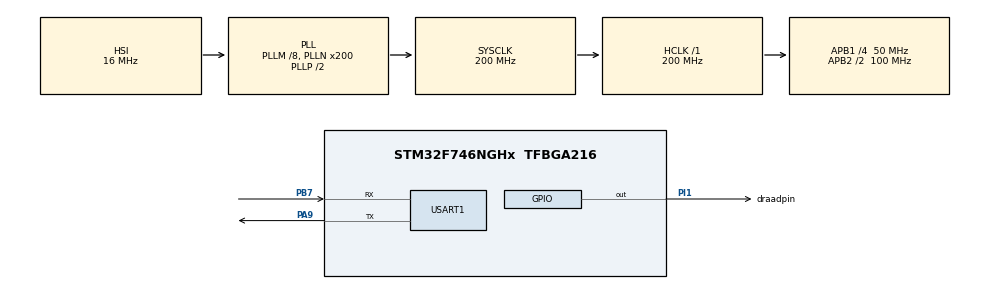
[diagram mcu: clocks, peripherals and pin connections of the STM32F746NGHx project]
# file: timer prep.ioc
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Mcu.Family=STM32F7
Mcu.Name=STM32F746NGHx
Mcu.Package=TFBGA216
NVIC.PriorityGroup=NVIC_PRIORITYGROUP_4
NVIC.TIM1_UP_TIM10_IRQn=true\:15\:0\:false\:false\:true\:false\:true
NVIC.TIM2_IRQn=true\:0\:0\:false\:false\:true\:true\:true
NVIC.TimeBase=TIM1_UP_TIM10_IRQn
NVIC.TimeBaseIP=TIM1
PA9.Mode=Asynchronous
PA9.Signal=USART1_TX
PB7.Mode=Asynchronous
PB7.Signal=USART1_RX
PI1.GPIO_Label=draadpin
PI1.Signal=GPIO_Output
ProjectManager.HeapSize=0x200
ProjectManager.StackSize=0x400
ProjectManager.TargetToolchain=STM32CubeIDE
RCC.AHBFreq_Value=200000000
RCC.APB1CLKDivider=RCC_HCLK_DIV4
RCC.APB1Freq_Value=50000000
RCC.APB1TimFreq_Value=100000000
RCC.APB2CLKDivider=RCC_HCLK_DIV2
RCC.APB2Freq_Value=100000000
RCC.APB2TimFreq_Value=200000000
RCC.CortexFreq_Value=200000000
RCC.HCLKFreq_Value=200000000
RCC.HSE_VALUE=25000000
RCC.HSI_VALUE=16000000
RCC.LSE_VALUE=32768
RCC.PLL48CLockSelection=RCC_CLK48SOURCE_PLLSAIP
RCC.PLLI2SN=100
RCC.PLLM=8
RCC.PLLN=200
RCC.PLLQ=9
RCC.PLLSAIN=384
RCC.PLLSAIP=RCC_PLLSAIP_DIV8
RCC.PLLSAIR=5
RCC.PLLSAIRDiv=RCC_PLLSAIDIVR_8
RCC.SDMMCClockSelection=RCC_SDMMC1CLKSOURCE_CLK48
RCC.SYSCLKFreq_VALUE=200000000
RCC.SYSCLKSource=RCC_SYSCLKSOURCE_PLLCLK
RCC.USBFreq_Value=96000000
RCC.VCOOutputFreq_Value=400000000
TIM2.AutoReloadPreload=TIM_AUTORELOAD_PRELOAD_ENABLE
TIM2.CounterMode=TIM_COUNTERMODE_DOWN
TIM2.Period=10
USART1.VirtualMode-Asynchronous=VM_ASYNC
VP_SYS_VS_tim1.Mode=TIM1
VP_TIM2_VS_ClockSourceINT.Mode=Internal
board=STM32F746G-DISCO

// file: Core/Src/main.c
/* USER CODE BEGIN Header */
/**
 ******************************************************************************
 * @file           : main.c
 * @brief          : Main program body
 ******************************************************************************
 * @attention
 *
 * <h2><center>&copy; Copyright (c) 2023 STMicroelectronics.
 * All rights reserved.</center></h2>
 *
 * This software component is licensed by ST under Ultimate Liberty license
 * SLA0044, the "License"; You may not use this file except in compliance with
 * the License. You may obtain a copy of the License at:
 *                             www.st.com/SLA0044
 *
 ******************************************************************************
 */
/* USER CODE END Header */
#include "main.h"

TIM_HandleTypeDef htim2;

UART_HandleTypeDef huart1;

void SystemClock_Config(void);
static void MX_GPIO_Init(void);
static void MX_USART1_UART_Init(void);
static void MX_TIM2_Init(void);

int main(void)
{

  /* MCU Configuration--------------------------------------------------------*/

  /* Reset of all peripherals, Initializes the Flash interface and the Systick. */
  HAL_Init();

  /* Configure the system clock */
  SystemClock_Config();

  /* Initialize all configured peripherals */
  MX_GPIO_Init();
  MX_USART1_UART_Init();
  MX_TIM2_Init();
  /* USER CODE BEGIN 2 */

	HAL_TIM_Base_Start_IT(&htim2);

  /* USER CODE END 2 */

  /* Infinite loop */
	while (1)
	{

	}
}

void SystemClock_Config(void)
{
  RCC_OscInitTypeDef RCC_OscInitStruct = {0};
  RCC_ClkInitTypeDef RCC_ClkInitStruct = {0};
  RCC_PeriphCLKInitTypeDef PeriphClkInitStruct = {0};

  /** Configure the main internal regulator output voltage
  */
  __HAL_RCC_PWR_CLK_ENABLE();
  __HAL_PWR_VOLTAGESCALING_CONFIG(PWR_REGULATOR_VOLTAGE_SCALE1);
  /** Initializes the RCC Oscillators according to the specified parameters
  * in the RCC_OscInitTypeDef structure.
  */
  RCC_OscInitStruct.OscillatorType = RCC_OSCILLATORTYPE_HSI;
  RCC_OscInitStruct.HSIState = RCC_HSI_ON;
  RCC_OscInitStruct.HSICalibrationValue = RCC_HSICALIBRATION_DEFAULT;
  RCC_OscInitStruct.PLL.PLLState = RCC_PLL_ON;
  RCC_OscInitStruct.PLL.PLLSource = RCC_PLLSOURCE_HSI;
  RCC_OscInitStruct.PLL.PLLM = 8;
  RCC_OscInitStruct.PLL.PLLN = 200;
  RCC_OscInitStruct.PLL.PLLP = RCC_PLLP_DIV2;
  RCC_OscInitStruct.PLL.PLLQ = 9;
  if (HAL_RCC_OscConfig(&RCC_OscInitStruct) != HAL_OK)
  {
    Error_Handler();
  }
  /** Activate the Over-Drive mode
  */
  if (HAL_PWREx_EnableOverDrive() != HAL_OK)
  {
    Error_Handler();
  }
  /** Initializes the CPU, AHB and APB buses clocks
  */
  RCC_ClkInitStruct.ClockType = RCC_CLOCKTYPE_HCLK|RCC_CLOCKTYPE_SYSCLK
                              |RCC_CLOCKTYPE_PCLK1|RCC_CLOCKTYPE_PCLK2;
  RCC_ClkInitStruct.SYSCLKSource = RCC_SYSCLKSOURCE_PLLCLK;
  RCC_ClkInitStruct.AHBCLKDivider = RCC_SYSCLK_DIV1;
  RCC_ClkInitStruct.APB1CLKDivider = RCC_HCLK_DIV4;
  RCC_ClkInitStruct.APB2CLKDivider = RCC_HCLK_DIV2;

  if (HAL_RCC_ClockConfig(&RCC_ClkInitStruct, FLASH_LATENCY_6) != HAL_OK)
  {
    Error_Handler();
  }
  PeriphClkInitStruct.PeriphClockSelection = RCC_PERIPHCLK_USART1;
  PeriphClkInitStruct.Usart1ClockSelection = RCC_USART1CLKSOURCE_PCLK2;
  if (HAL_RCCEx_PeriphCLKConfig(&PeriphClkInitStruct) != HAL_OK)
  {
    Error_Handler();
  }
}

static void MX_TIM2_Init(void)
{

  TIM_ClockConfigTypeDef sClockSourceConfig = {0};
  TIM_MasterConfigTypeDef sMasterConfig = {0};

  htim2.Instance = TIM2;
  htim2.Init.Prescaler = 0;
  htim2.Init.CounterMode = TIM_COUNTERMODE_DOWN;
  htim2.Init.Period = 10;
  htim2.Init.ClockDivision = TIM_CLOCKDIVISION_DIV1;
  htim2.Init.AutoReloadPreload = TIM_AUTORELOAD_PRELOAD_ENABLE;
  if (HAL_TIM_Base_Init(&htim2) != HAL_OK)
  {
    Error_Handler();
  }
  sClockSourceConfig.ClockSource = TIM_CLOCKSOURCE_INTERNAL;
  if (HAL_TIM_ConfigClockSource(&htim2, &sClockSourceConfig) != HAL_OK)
  {
    Error_Handler();
  }
  sMasterConfig.MasterOutputTrigger = TIM_TRGO_RESET;
  sMasterConfig.MasterSlaveMode = TIM_MASTERSLAVEMODE_DISABLE;
  if (HAL_TIMEx_MasterConfigSynchronization(&htim2, &sMasterConfig) != HAL_OK)
  {
    Error_Handler();
  }

}

static void MX_USART1_UART_Init(void)
{

  huart1.Instance = USART1;
  huart1.Init.BaudRate = 115200;
  huart1.Init.WordLength = UART_WORDLENGTH_8B;
  huart1.Init.StopBits = UART_STOPBITS_1;
  huart1.Init.Parity = UART_PARITY_NONE;
  huart1.Init.Mode = UART_MODE_TX_RX;
  huart1.Init.HwFlowCtl = UART_HWCONTROL_NONE;
  huart1.Init.OverSampling = UART_OVERSAMPLING_16;
  huart1.Init.OneBitSampling = UART_ONE_BIT_SAMPLE_DISABLE;
  huart1.AdvancedInit.AdvFeatureInit = UART_ADVFEATURE_NO_INIT;
  if (HAL_UART_Init(&huart1) != HAL_OK)
  {
    Error_Handler();
  }

}

static void MX_GPIO_Init(void)
{
  GPIO_InitTypeDef GPIO_InitStruct = {0};

  /* GPIO Ports Clock Enable */
  __HAL_RCC_GPIOB_CLK_ENABLE();
  __HAL_RCC_GPIOI_CLK_ENABLE();
  __HAL_RCC_GPIOA_CLK_ENABLE();

  /*Configure GPIO pin Output Level */
  HAL_GPIO_WritePin(draadpin_GPIO_Port, draadpin_Pin, GPIO_PIN_RESET);

  /*Configure GPIO pin : draadpin_Pin */
  GPIO_InitStruct.Pin = draadpin_Pin;
  GPIO_InitStruct.Mode = GPIO_MODE_OUTPUT_PP;
  GPIO_InitStruct.Pull = GPIO_NOPULL;
  GPIO_InitStruct.Speed = GPIO_SPEED_FREQ_LOW;
  HAL_GPIO_Init(draadpin_GPIO_Port, &GPIO_InitStruct);

}

void HAL_TIM_PeriodElapsedCallback(TIM_HandleTypeDef *htim)
{
  if (htim->Instance == TIM1) {
    HAL_IncTick();
  }
  /* USER CODE BEGIN Callback 1 */
	if(htim->Instance == TIM2){
		HAL_GPIO_TogglePin(draadpin_GPIO_Port, draadpin_Pin);
	}
  /* USER CODE END Callback 1 */
}

void Error_Handler(void)
{
	__disable_irq();
	while (1)
	{
	}
}

/************************ (C) COPYRIGHT STMicroelectronics *****END OF FILE****/
